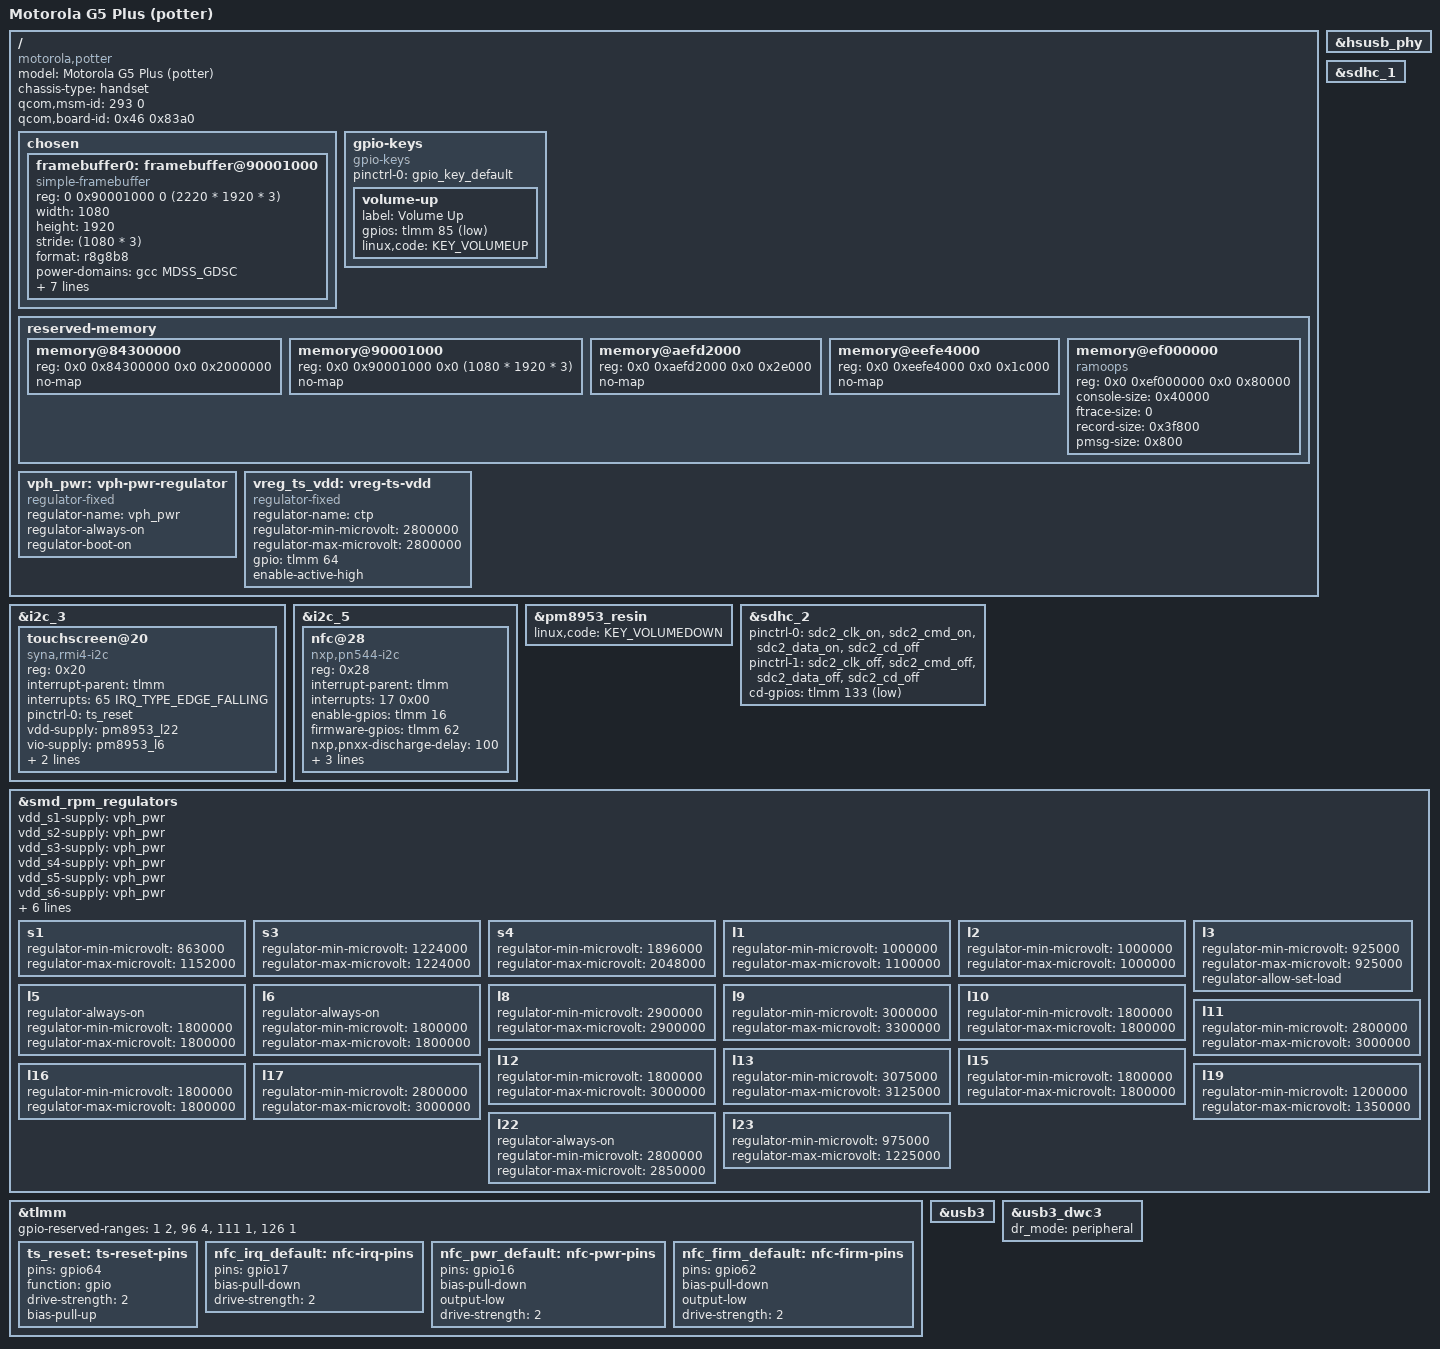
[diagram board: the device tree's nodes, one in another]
/* Copyright (c) 2022 The Linux Foundation. All rights reserved.
 *
 * This program is free software; you can redistribute it and/or modify
 * it under the terms of the GNU General Public License version 2 and
 * only version 2 as published by the Free Software Foundation.
 *
 * This program is distributed in the hope that it will be useful,
 * but WITHOUT ANY WARRANTY; without even the implied warranty of
 * MERCHANTABILITY or FITNESS FOR A PARTICULAR PURPOSE.  See the
 * GNU General Public License for more details.
 */
/dts-v1/;

#include "msm8953-pm8953.dtsi"

/ {
	model = "Motorola G5 Plus (potter)";
	compatible = "motorola,potter", "qcom,msm8953";
	chassis-type = "handset";
	qcom,msm-id = <293 0>;
	qcom,board-id = <0x46 0x83a0>;

	chosen {
		#address-cells = <2>;
		#size-cells = <2>;
		ranges;

		framebuffer0: framebuffer@90001000 {
			compatible = "simple-framebuffer";
			reg = <0 0x90001000 0 (2220 * 1920 * 3)>;

			width = <1080>;
			height = <1920>;
			stride = <(1080 * 3)>;
			format = "r8g8b8";

			power-domains = <&gcc MDSS_GDSC>;

			clocks = <&gcc GCC_MDSS_AHB_CLK>,
				 <&gcc GCC_MDSS_AXI_CLK>,
				 <&gcc GCC_MDSS_VSYNC_CLK>,
				 <&gcc GCC_MDSS_MDP_CLK>,
				 <&gcc GCC_MDSS_BYTE0_CLK>,
				 <&gcc GCC_MDSS_PCLK0_CLK>,
				 <&gcc GCC_MDSS_ESC0_CLK>;
		};
	};

	gpio-keys {
		compatible = "gpio-keys";

		pinctrl-names = "default";
		pinctrl-0 = <&gpio_key_default>;

		volume-up {
			label = "Volume Up";
			gpios = <&tlmm 85 GPIO_ACTIVE_LOW>;
			linux,code = <KEY_VOLUMEUP>;
		};
	};

	reserved-memory {
		/delete-node/memory@85b00000;

		memory@84300000 {
			reg = <0x0 0x84300000 0x0 0x2000000>;
			no-map;
		};

		memory@90001000 {
			reg = <0x0 0x90001000 0x0 (1080 * 1920 * 3)>;
			no-map;
		};

		memory@aefd2000 {
			reg = <0x0 0xaefd2000 0x0 0x2e000>;
			no-map;
		};

		memory@eefe4000 {
			reg = <0x0 0xeefe4000 0x0 0x1c000>;
			no-map;
		};

		memory@ef000000 {
			compatible = "ramoops";
			reg = <0x0 0xef000000 0x0 0x80000>;
			console-size = <0x40000>;
			ftrace-size = <0>;
			record-size = <0x3f800>;
			pmsg-size = <0x800>;
		};
	};

	vph_pwr: vph-pwr-regulator {
		compatible = "regulator-fixed";
		regulator-name = "vph_pwr";
		regulator-always-on;
		regulator-boot-on;
	};

	vreg_ts_vdd: vreg-ts-vdd {
		compatible = "regulator-fixed";
		regulator-name = "ctp";

		regulator-min-microvolt = <2800000>;
		regulator-max-microvolt = <2800000>;

		gpio = <&tlmm 64 GPIO_ACTIVE_HIGH>;
		enable-active-high;
	};
};

&hsusb_phy {
	status = "okay";
};

&i2c_3 {
	status = "okay";

	touchscreen@20 {
		reg = <0x20>;
		compatible = "syna,rmi4-i2c";

		interrupt-parent = <&tlmm>;
		interrupts = <65 IRQ_TYPE_EDGE_FALLING>;

		pinctrl-names = "default";
		pinctrl-0 = <&ts_reset>;

		vdd-supply = <&pm8953_l22>;
		vio-supply = <&pm8953_l6>;

		syna,reset-delay-ms = <200>;
		syna,startup-delay-ms = <500>;
	};
};

&i2c_5 {
	status = "okay";

	nfc@28 {
		compatible = "nxp,pn544-i2c";
		reg = <0x28>;
		interrupt-parent = <&tlmm>;
		interrupts = <17 0x00>; // FIXME

		enable-gpios = <&tlmm 16 GPIO_ACTIVE_HIGH>; /* EN */
		firmware-gpios = <&tlmm 62 GPIO_ACTIVE_HIGH>; /* Firmware */

		nxp,pnxx-discharge-delay = <100>;
		nxp,pnxx-ven-inv-polarity = <0x00>;

		pinctrl-names = "default";
		pinctrl-0 = <&nfc_irq_default &nfc_pwr_default &nfc_firm_default>;
	};
};

&pm8953_resin {
	status = "okay";
	linux,code = <KEY_VOLUMEDOWN>;
};

&sdhc_1 {
	status = "okay";
};

&sdhc_2 {
	status = "okay";

	pinctrl-names = "default", "sleep";
	pinctrl-0 = <&sdc2_clk_on &sdc2_cmd_on &sdc2_data_on &sdc2_cd_off>;
	pinctrl-1 = <&sdc2_clk_off &sdc2_cmd_off &sdc2_data_off &sdc2_cd_off>;

	cd-gpios = <&tlmm 133 GPIO_ACTIVE_LOW>;
};

&smd_rpm_regulators {
	vdd_s1-supply = <&vph_pwr>;
	vdd_s2-supply = <&vph_pwr>;
	vdd_s3-supply = <&vph_pwr>;
	vdd_s4-supply = <&vph_pwr>;
	vdd_s5-supply = <&vph_pwr>;
	vdd_s6-supply = <&vph_pwr>;
	vdd_s7-supply = <&vph_pwr>;
	vdd_l1-supply = <&pm8953_s3>;
	vdd_l2_l3-supply = <&pm8953_s3>;
	vdd_l4_l5_l6_l7_l16_l19-supply = <&pm8953_s4>;
	vdd_l8_l11_l12_l13_l14_l15-supply = <&vph_pwr>;
	vdd_l9_l10_l17_l18_l22-supply = <&vph_pwr>;

	s1 {
		regulator-min-microvolt = <863000>;
		regulator-max-microvolt = <1152000>;
	};

	s3 {
		regulator-min-microvolt = <1224000>;
		regulator-max-microvolt = <1224000>;
	};

	s4 {
		regulator-min-microvolt = <1896000>;
		regulator-max-microvolt = <2048000>;
	};

	l1 {
		regulator-min-microvolt = <1000000>;
		regulator-max-microvolt = <1100000>;
	};

	l2 {
		regulator-min-microvolt = <1000000>;
		regulator-max-microvolt = <1000000>;
	};

	l3 {
		regulator-min-microvolt = <925000>;
		regulator-max-microvolt = <925000>;
		regulator-allow-set-load;
	};

	l5 {
		/* May fix sdcard detection */
		regulator-always-on;
		regulator-min-microvolt = <1800000>;
		regulator-max-microvolt = <1800000>;
	};

	l6 {
		regulator-always-on;
		regulator-min-microvolt = <1800000>;
		regulator-max-microvolt = <1800000>;
	};

	l8 {
		regulator-min-microvolt = <2900000>;
		regulator-max-microvolt = <2900000>;
	};

	l9 {
		regulator-min-microvolt = <3000000>;
		regulator-max-microvolt = <3300000>;
	};

	l10 {
		regulator-min-microvolt = <1800000>;
		regulator-max-microvolt = <1800000>;
	};

	l11 {
		regulator-min-microvolt = <2800000>;
		regulator-max-microvolt = <3000000>;
	};

	l12 {
		regulator-min-microvolt = <1800000>;
		regulator-max-microvolt = <3000000>;
	};

	l13 {
		regulator-min-microvolt = <3075000>;
		regulator-max-microvolt = <3125000>;
	};

	l15 {
		regulator-min-microvolt = <1800000>;
		regulator-max-microvolt = <1800000>;
	};

	l16 {
		regulator-min-microvolt = <1800000>;
		regulator-max-microvolt = <1800000>;
	};

	l17 {
		regulator-min-microvolt = <2800000>;
		regulator-max-microvolt = <3000000>;
	};

	l19 {
		regulator-min-microvolt = <1200000>;
		regulator-max-microvolt = <1350000>;
	};

	l22 {
		regulator-always-on;
		regulator-min-microvolt = <2800000>;
		regulator-max-microvolt = <2850000>;
	};

	l23 {
		regulator-min-microvolt = <975000>;
		regulator-max-microvolt = <1225000>;
	};
};

&tlmm {
	gpio-reserved-ranges = <1 2>, <96 4>, <111 1>, <126 1>;

	ts_reset: ts-reset-pins {
		pins = "gpio64";
		function = "gpio";
		drive-strength = <2>;
		bias-pull-up;
	};

	nfc_irq_default: nfc-irq-pins {
		pins = "gpio17";
		bias-pull-down;
		drive-strength = <2>;
	};

	nfc_pwr_default: nfc-pwr-pins {
		pins = "gpio16";
		bias-pull-down;
		output-low;
		drive-strength = <2>;
	};

	nfc_firm_default: nfc-firm-pins {
		pins = "gpio62";
		bias-pull-down;
		output-low;
		drive-strength = <2>;
	};
};

&usb3 {
	status = "okay";
};

&usb3_dwc3 {
	dr_mode = "peripheral";
};
